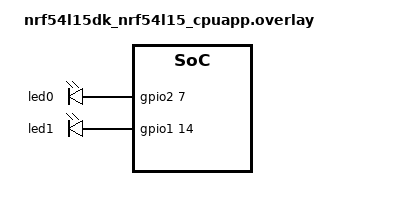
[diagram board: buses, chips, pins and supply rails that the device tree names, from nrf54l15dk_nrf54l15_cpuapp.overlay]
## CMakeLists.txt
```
# SPDX-License-Identifier: Apache-2.0

cmake_minimum_required(VERSION 3.20.0)
find_package(Zephyr REQUIRED HINTS $ENV{ZEPHYR_BASE})
project(nrf54l15dk_blinky)

target_sources(app PRIVATE src/main.c
                           src/button.c)
target_sources_ifdef(CONFIG_MYFUNCTION app PRIVATE src/myFunc.c)
```

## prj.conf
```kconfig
CONFIG_GPIO=y
CONFIG_MYFUNCTION=y
CONFIG_LOG=y
```

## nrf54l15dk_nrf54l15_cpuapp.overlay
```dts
// To get started, press Ctrl+Space to bring up the completion menu and view the available nodes.

// You can also use the buttons in the sidebar to perform actions on nodes.
// Actions currently available include:

// * Enabling / disabling the node
// * Adding the bus to a bus
// * Removing the node
// * Connecting ADC channels

// For more help, browse the DeviceTree documentation at https://docs.zephyrproject.org/latest/guides/dts/index.html
// You can also visit the nRF DeviceTree extension documentation at https://docs.nordicsemi.com/bundle/nrf-connect-vscode/page/guides/ncs_configure_app.html#devicetree-support-in-the-extension


/delete-node/ &led2;
/delete-node/ &led3;


&led0 {
	gpios = <&gpio2 7 GPIO_ACTIVE_HIGH>;
};

&led1 {
	gpios = <&gpio1 14 GPIO_ACTIVE_HIGH>;
};


/ {
	aliases {
		/delete-property/ led2;
		/delete-property/ led3;
	};
};
```

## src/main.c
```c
/*
 *
 * gpio、按键、日志、自定义函数示例
 */

#include <stdbool.h>
#include <sys/_intsup.h>
#include <zephyr/drivers/gpio.h>
#include <zephyr/kernel.h>
#include <zephyr/logging/log.h>
#include "button.h"
#ifdef CONFIG_MYFUNCTION
#include "myFunc.h"
#endif

/* 1000 msec = 1 sec */
#define SLEEP_TIME_MS 1000

/* The devicetree node identifier for the "led0" alias. */
#define LED0_NODE    DT_ALIAS(led0)
#define LED1_NODE    DT_ALIAS(led1)
#define BUTTON0_NODE DT_ALIAS(sw0)
// #define BUTTON0_NODE DT_NODELABEL(button0)

LOG_MODULE_REGISTER(blinking, LOG_LEVEL_INF);

/*
 * A build error on this line means your board is unsupported.
 * See the sample documentation for information on how to fix this.
 */
static const struct gpio_dt_spec led0 = GPIO_DT_SPEC_GET(LED0_NODE, gpios);
static const struct gpio_dt_spec led1 = GPIO_DT_SPEC_GET(LED1_NODE, gpios);
const struct gpio_dt_spec button0     = GPIO_DT_SPEC_GET(BUTTON0_NODE, gpios);

int main(void) {
    int ret;
    bool led_state = true;
    int led1_state = 0;
    button_init_dt(&button0, NULL);
    if (!gpio_is_ready_dt(&led0)) {
        return 0;
    }
    if (!gpio_is_ready_dt(&led1)) {
        return 0;
    }

    ret = gpio_pin_configure_dt(&led0, GPIO_OUTPUT_ACTIVE);
    if (ret < 0) {
        return 0;
    }
    ret = gpio_pin_configure_dt(&led1, GPIO_OUTPUT_ACTIVE);
    if (ret < 0) {
        return 0;
    }

#ifdef CONFIG_LOG
    int exercise_num = 2;
    uint8_t data[]   = {0x00, 0x01, 0x02, 0x03, 0x04, 0x05, 0x06, 0x07, 'H', 'e', 'l', 'l', 'o'};
    LOG_DBG("A log message in debug level");
    LOG_INF("Exercise %d", exercise_num);
    LOG_WRN("A log message in warning level!");
    LOG_ERR("A log message in Error level!");
    //Hexdump some data
    LOG_HEXDUMP_INF(data, sizeof(data), "Sample Data!");
#endif
    while (1) {
        ret = gpio_pin_toggle_dt(&led0);
        if (ret < 0) {
            return 0;
        }
        // 这里形参value是逻辑电平，即1表示灯亮，和设备树中的GPIO_ACTIVE_HIGH一致，物理上1为亮，0为灭；
        // 如果GPIO_ACTIVE_LOW，即物理上1为灭，0为亮；
        gpio_pin_set_dt(&led1, 1);
        led1_state = gpio_pin_get_dt(&led1);
        LOG_INF("LED1 state: %d\n", led1_state);
        k_msleep(1000);
        // 同样，读取到的也是逻辑电平
        gpio_pin_set_dt(&led1, 0);
        led1_state = gpio_pin_get_dt(&led1);
        LOG_INF("LED1 state: %d\n", led1_state);
        led_state = !led_state;
        LOG_INF("LED state: %s\n", led_state ? "ON" : "OFF");
#ifdef CONFIG_MYFUNCTION
        int a = 3, b = 4;
        LOG_INF("The sum of %2d and %2d is %2d\n", a, b, sum(a, b));
#else
        LOG_INF("MYFUNCTION not enabled\n");

#endif
        k_msleep(SLEEP_TIME_MS);
    }
    return 0;
}
```

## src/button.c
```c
#include <zephyr/drivers/gpio.h>
#include <zephyr/kernel.h>
#include "zephyr/sys/util_macro.h"
#include "zephyr/toolchain.h"
#include <zephyr/logging/log.h>
#include "button.h"
LOG_MODULE_REGISTER(button, LOG_LEVEL_INF);

static struct gpio_callback button0_cb_data;
void button0_isr(const struct device* port, struct gpio_callback* cb, gpio_port_pins_t pins);

static void cooldown_work_cb(struct k_work* work);

K_WORK_DELAYABLE_DEFINE(cooldown_work, cooldown_work_cb);

int button_init_dt(const struct gpio_dt_spec* spec, button_evt_cb_t cb) {
    int ret;
    if (!gpio_is_ready_dt(spec)) {
        return 0;
    };
    ret = gpio_pin_configure_dt(spec, GPIO_INPUT);
    if (ret < 0) {
        return 0;
    }
    ret = gpio_pin_interrupt_configure_dt(spec, GPIO_INT_EDGE_BOTH);
    if (ret < 0) {
        return 0;
    }
    gpio_init_callback(&button0_cb_data, button0_isr, BIT(spec->pin));
    gpio_add_callback_dt(spec, &button0_cb_data);
    k_work_init_delayable(&cooldown_work, cooldown_work_cb);
    return 0;
}

void button0_isr(const struct device* port, struct gpio_callback* cb, gpio_port_pins_t pins) {
    // gpio_pin_toggle_dt(&led1);
    k_work_reschedule(&cooldown_work, K_MSEC(15));
    k_work_schedule(&cooldown_work, K_MSEC(15));
    LOG_INF("PORT: %p, PINS: %d", port, pins);
}

extern const struct gpio_dt_spec button0;

static void cooldown_work_cb(struct k_work* work) {
    ARG_UNUSED(work);
    int val             = gpio_pin_get_dt(&button0);
    enum button_evt evt = val == 1 ? BUTTON_EVT_PRESSED : BUTTON_EVT_RELEASED;
    switch (evt) {
        case BUTTON_EVT_PRESSED:  LOG_INF("Button pressed"); break;
        case BUTTON_EVT_RELEASED: LOG_INF("Button released"); break;
        default:                  break;
    }
    LOG_INF("Cooldown callback executed");
}
```
